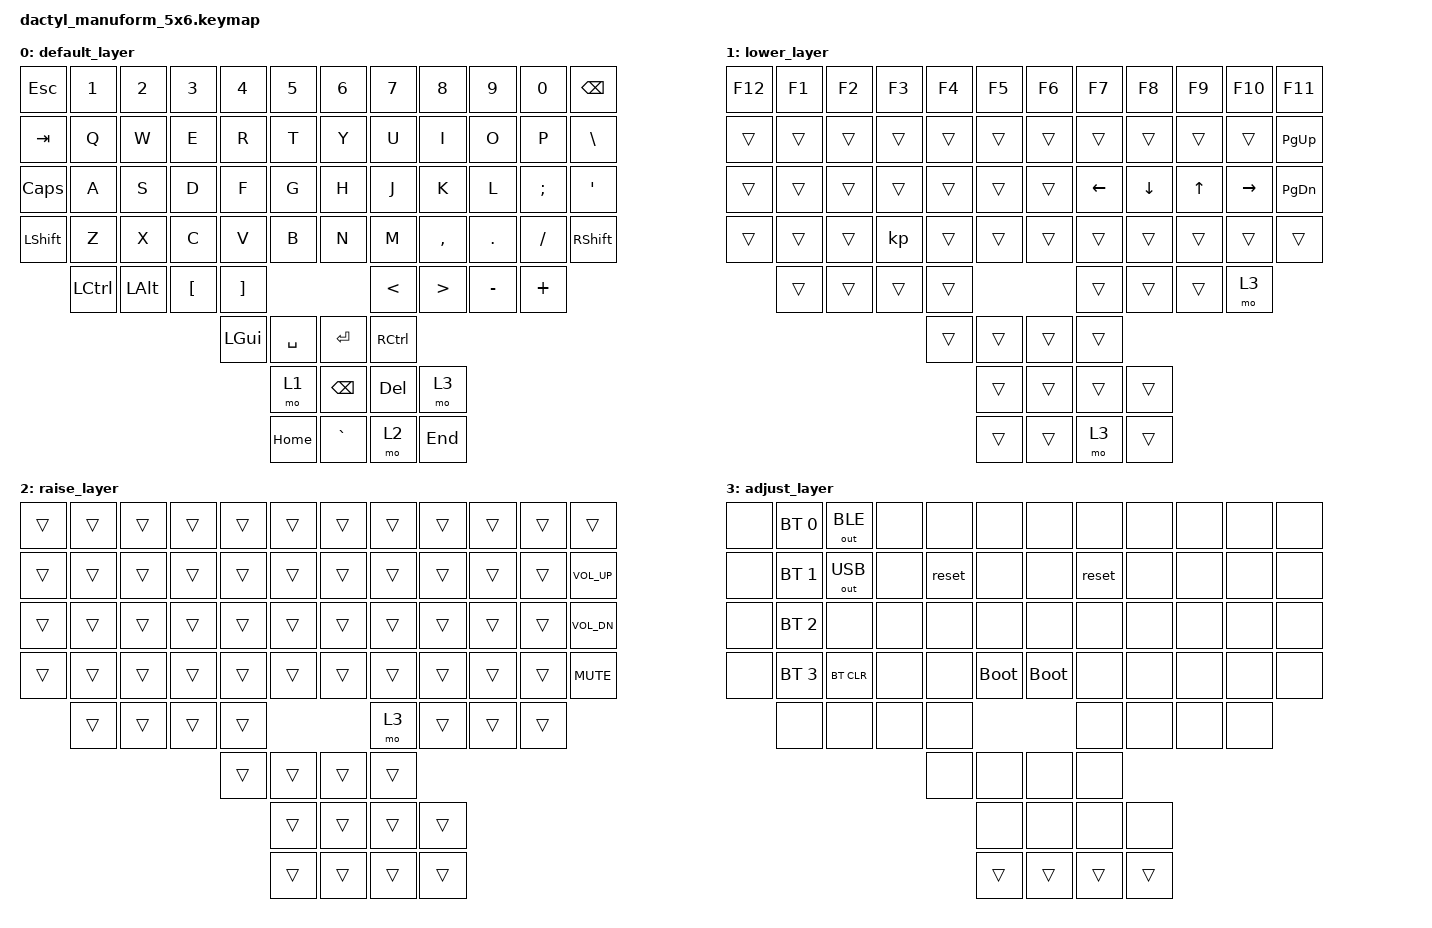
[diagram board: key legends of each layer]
#include <behaviors.dtsi>
#include <dt-bindings/zmk/keys.h>
#include <dt-bindings/zmk/bt.h>
#include <dt-bindings/zmk/outputs.h>

#define DEFAULT 0
#define LWR 1
#define RSE 2
#define ADJ 3

/ {
    keymap {
        compatible = "zmk,keymap";

        default_layer {
            bindings = <
    &kp ESC             &kp N1            &kp N2            &kp N3              &kp N4     &kp N5                                &kp N6     &kp N7                    &kp N8                     &kp N9               &kp N0                 &kp BSPC
    &kp TAB              &kp Q             &kp W             &kp E               &kp R      &kp T                                 &kp Y      &kp U                     &kp I                      &kp O                &kp P            &kp BACKSLASH
   &kp CAPS              &kp A             &kp S             &kp D               &kp F      &kp G                                 &kp H      &kp J                     &kp K                      &kp L             &kp SEMI                  &kp SQT
 &kp LSHIFT              &kp Z             &kp X             &kp C               &kp V      &kp B                                 &kp N      &kp M                 &kp COMMA                    &kp DOT             &kp FSLH                &kp RSHFT
             &kp LCTRL          &kp LALT          &kp LBKT          &kp RBKT                                                                        &kp LESS_THAN             &kp GREATER_THAN           &kp MINUS            &kp PLUS
                                                                              &kp LGUI  &kp SPACE                             &kp ENTER  &kp RCTRL
                                                                                            &mo 1  &kp BACKSPACE  &kp DELETE      &mo 3
                                                                                         &kp HOME      &kp GRAVE       &mo 2    &kp END
            >;
        };

        lower_layer {
            bindings = <
 &kp F12          &kp F1          &kp F2          &kp F3          &kp F4  &kp F5                  &kp F6    &kp F7            &kp F8          &kp F9            &kp F10                &kp F11
  &trans          &trans          &trans          &trans          &trans  &trans                  &trans    &trans            &trans          &trans             &trans            &kp PAGE_UP
  &trans          &trans          &trans          &trans          &trans  &trans                  &trans  &kp LEFT          &kp DOWN          &kp UP          &kp RIGHT          &kp PAGE_DOWN
  &trans          &trans          &trans             &kp          &trans  &trans                  &trans    &trans            &trans          &trans             &trans                 &trans
          &trans          &trans          &trans          &trans                                                    &trans            &trans          &trans              &mo 3
                                                                  &trans  &trans                  &trans    &trans
                                                                          &trans  &trans  &trans  &trans
                                                                          &trans  &trans   &mo 3  &trans
            >;
        };

        raise_layer {
            bindings = <
 &trans          &trans          &trans          &trans          &trans  &trans                  &trans  &trans          &trans          &trans          &trans                &trans
 &trans          &trans          &trans          &trans          &trans  &trans                  &trans  &trans          &trans          &trans          &trans          &kp K_VOL_UP
 &trans          &trans          &trans          &trans          &trans  &trans                  &trans  &trans          &trans          &trans          &trans          &kp K_VOL_DN
 &trans          &trans          &trans          &trans          &trans  &trans                  &trans  &trans          &trans          &trans          &trans            &kp K_MUTE
         &trans          &trans          &trans          &trans                                                   &mo 3          &trans          &trans          &trans
                                                                 &trans  &trans                  &trans  &trans
                                                                         &trans  &trans  &trans  &trans
                                                                         &trans  &trans  &trans  &trans
            >;
        };

        adjust_layer {
            bindings = <
  &none          &bt BT_SEL 0          &out OUT_BLE           &none           &none        &none                        &none   &none           &none           &none           &none           &none
  &none          &bt BT_SEL 1          &out OUT_USB           &none          &reset        &none                        &none  &reset           &none           &none           &none           &none
  &none          &bt BT_SEL 2                 &none           &none           &none        &none                        &none   &none           &none           &none           &none           &none
  &none          &bt BT_SEL 3            &bt BT_CLR           &none           &none  &bootloader                  &bootloader   &none           &none           &none           &none           &none
          &none                 &none                 &none           &none                                                             &none           &none           &none           &none
                                                                              &none        &none                        &none   &none
                                                                                           &none   &none   &none        &none
                                                                                          &trans  &trans  &trans       &trans
            >;
        };
    };
};
